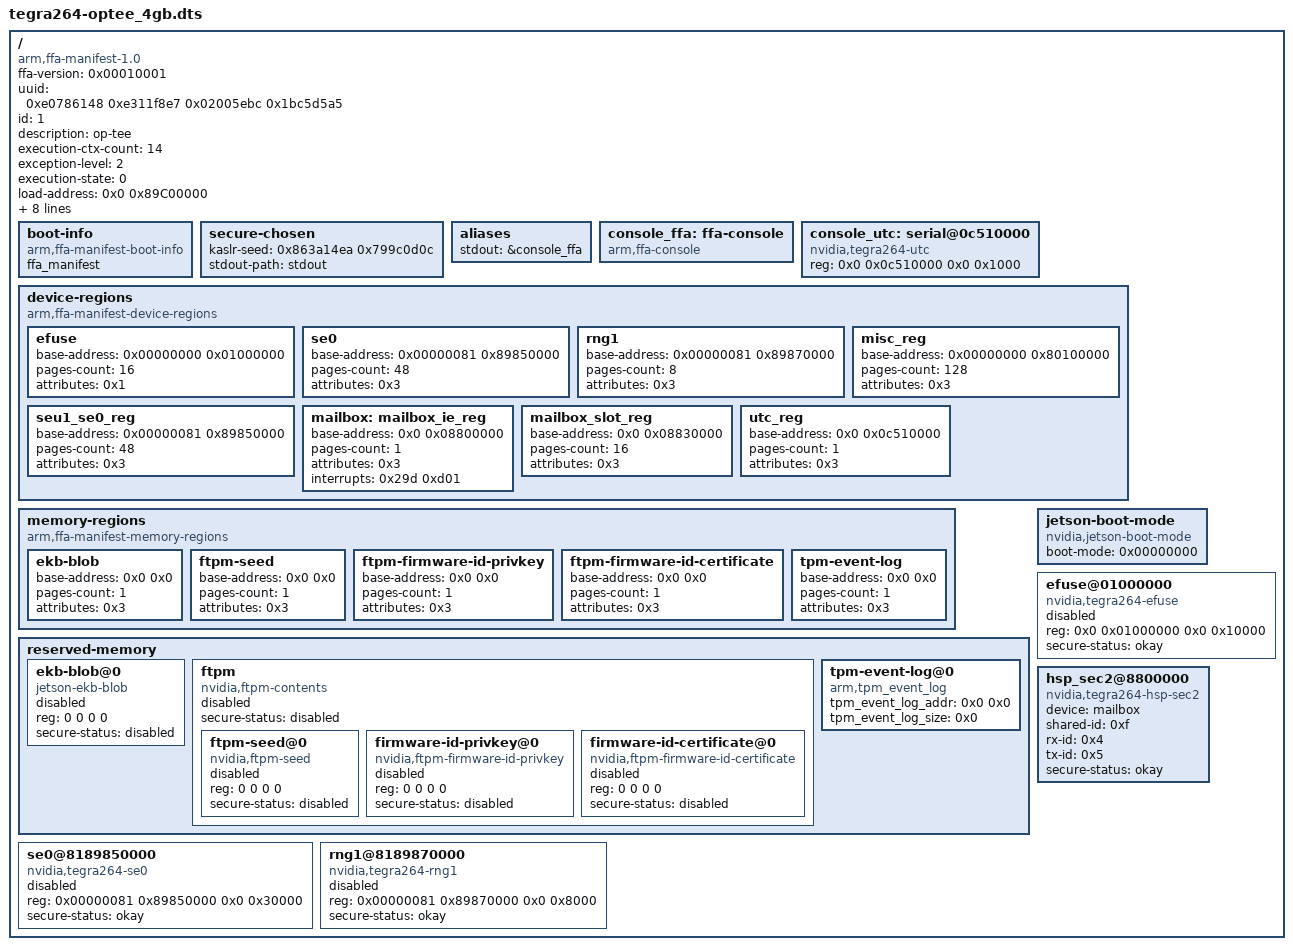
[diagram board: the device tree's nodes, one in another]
/dts-v1/;
/ {
 compatible = "arm,ffa-manifest-1.0";
 ffa-version = <0x00010001>;
 uuid = <0xe0786148 0xe311f8e7 0x02005ebc 0x1bc5d5a5>;
 id = <1>;
 description = "op-tee";
 execution-ctx-count = <14>;
 exception-level = <2>;
 execution-state = <0>;
 load-address = <0x0 0x89C00000>;
 entrypoint-offset = <0x0 0x00004000>;
 xlat-granule = <0>;
 boot-order = <0>;
 messaging-method = <0x3>;
 ns-interrupts-action = <1>;
 notification-support;
 mem-size = <0xFFE00000>;
 #address-cells = <2>;
 #size-cells = <2>;
 gp-register-num = <0x0>;
 boot-info {
  compatible = "arm,ffa-manifest-boot-info";
  ffa_manifest;
 };
 secure-chosen {
  kaslr-seed = <0x863a14ea 0x799c0d0c>;
  stdout-path = "stdout";
 };
 aliases {
  stdout = &console_ffa;
 };
 console_ffa: ffa-console {
  compatible = "arm,ffa-console";
 };
 console_utc: serial@0c510000 {
  compatible = "nvidia,tegra264-utc";
  reg = <0x0 0x0c510000 0x0 0x1000>;
 };
 device-regions {
  compatible = "arm,ffa-manifest-device-regions";
  efuse {
   base-address = <0x00000000 0x01000000>;
   pages-count = <16>;
   attributes = <0x1>;
  };
  se0 {
   base-address = <0x00000081 0x89850000>;
   pages-count = <48>;
   attributes = <0x3>;
  };
  rng1 {
   base-address = <0x00000081 0x89870000>;
   pages-count = <8>;
   attributes = <0x3>;
  };
  misc_reg {
   base-address = <0x00000000 0x80100000>;
   pages-count = <128>;
   attributes = <0x3>;
  };
  seu1_se0_reg {
   base-address = <0x00000081 0x89850000>;
   pages-count = <48>;
   attributes = <0x3>;
  };
  mailbox: mailbox_ie_reg {
   base-address = <0x0 0x08800000>;
   pages-count = <1>;
   attributes = <0x3>;
   interrupts = <0x29d 0xd01>;
  };
  mailbox_slot_reg {
   base-address = <0x0 0x08830000>;
   pages-count = <16>;
   attributes = <0x3>;
  };
  utc_reg {
   base-address = <0x0 0x0c510000>;
   pages-count = <1>;
   attributes = <0x3>;
  };
 };
 memory-regions {
  compatible = "arm,ffa-manifest-memory-regions";
  ekb-blob {
   base-address = <0x0 0x0>;
   pages-count = <1>;
   attributes = <0x3>;
  };
  ftpm-seed {
   base-address = <0x0 0x0>;
   pages-count = <1>;
   attributes = <0x3>;
  };
  ftpm-firmware-id-privkey {
   base-address = <0x0 0x0>;
   pages-count = <1>;
   attributes = <0x3>;
  };
  ftpm-firmware-id-certificate {
   base-address = <0x0 0x0>;
   pages-count = <1>;
   attributes = <0x3>;
  };
  tpm-event-log {
   base-address = <0x0 0x0>;
   pages-count = <1>;
   attributes = <0x3>;
  };
 };
 reserved-memory {
  #address-cells = <2>;
  #size-cells = <2>;
  ekb-blob@0 {
   compatible = "jetson-ekb-blob";
   reg = <0 0 0 0>;
   status = "disabled";
   secure-status = "disabled";
  };
  ftpm {
   compatible = "nvidia,ftpm-contents";
   status = "disabled";
   secure-status = "disabled";
   #address-cells = <2>;
   #size-cells = <2>;
   ftpm-seed@0 {
    compatible = "nvidia,ftpm-seed";
    reg = <0 0 0 0>;
    status = "disabled";
    secure-status = "disabled";
   };
   firmware-id-privkey@0 {
    compatible = "nvidia,ftpm-firmware-id-privkey";
    reg = <0 0 0 0>;
    status = "disabled";
    secure-status = "disabled";
   };
   firmware-id-certificate@0 {
    compatible = "nvidia,ftpm-firmware-id-certificate";
    reg = <0 0 0 0>;
    status = "disabled";
    secure-status = "disabled";
   };
  };
  tpm-event-log@0 {
   compatible = "arm,tpm_event_log";
   tpm_event_log_addr = <0x0 0x0>;
   tpm_event_log_size = <0x0>;
  };
 };
 jetson-boot-mode {
  compatible = "nvidia,jetson-boot-mode";
  boot-mode= <0x00000000>;
 };
 efuse@01000000 {
  compatible = "nvidia,tegra264-efuse";
  reg = <0x0 0x01000000 0x0 0x10000>;
  status = "disabled";
  secure-status = "okay";
 };
 se0@8189850000 {
  compatible = "nvidia,tegra264-se0";
  reg = <0x00000081 0x89850000 0x0 0x30000>;
  status = "disabled";
  secure-status = "okay";
 };
 rng1@8189870000 {
  compatible = "nvidia,tegra264-rng1";
  reg = <0x00000081 0x89870000 0x0 0x8000>;
  status = "disabled";
  secure-status = "okay";
 };
 hsp_sec2@8800000 {
  compatible = "nvidia,tegra264-hsp-sec2";
  device = <&mailbox>;
  shared-id = <0xf>;
  rx-id = <0x4>;
  tx-id = <0x5>;
  secure-status = "okay";
 };
};
